AUTOSAR XML (schema 4-2-2)
package /Acme/Types
  base type Octet: category=FIXED_LENGTH, base-type-size=8, base-type-encoding=NONE, native-declaration=uint8
  impl type RecordId: category=VALUE, base-type=Octet
package /Acme/Interfaces
  client server interface IRecords
    operation ReadRecord
      arg id: type=RecordId, direction=IN
    operation ReadOther
      arg id: type=RecordId, direction=IN
    operation Reset
  client server interface IOther
    operation Ping
  sender receiver interface ISignals
    data Value: type=RecordId
package /Acme/Components
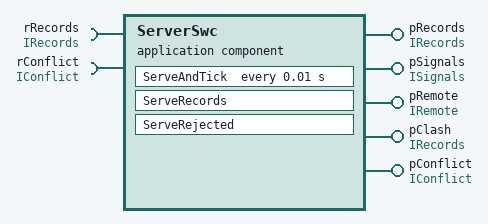
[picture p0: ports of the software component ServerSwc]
  application sw component type ServerSwc
    provide port pRecords: provided-interface=IRecords
      provided-com-specs:
        operation=ReadRecord, queue-length=1
        operation=ReadOther, queue-length=2
        operation=Reset, queue-length=1
    provide port pSignals: provided-interface=ISignals
    require port rRecords: required-interface=IRecords
    provide port pRemote: provided-interface=IRemote
    provide port pClash: provided-interface=IRecords
    provide port pConflict: provided-interface=IConflict
    require port rConflict: required-interface=IConflict
    provide/require port prRecords: provided-required-interface=IRecords
    behavior Behavior
      operation invoked event E_ReadRecord: start-on-event=ServeRecords, operation=pRecords.ReadRecord
      operation invoked event E_ReadOther: start-on-event=ServeRecords, operation=pRecords.ReadOther
      timing event E_Tick: start-on-event=ServeAndTick, period=0.01
      13 x operation invoked event:
        E_Reset: start-on-event=ServeAndTick, operation=pRecords.Reset
        E_Remote: start-on-event=ServeRejected, operation=pRemote.Serve
        E_Clash: start-on-event=ServeRejected, operation=pClash.ReadRecord
        E_Conflict: start-on-event=ServeRejected, operation=pConflict.Serve
        E_Signal: start-on-event=ServeRejected, operation=pSignals.Value
        E_Require: start-on-event=ServeRejected, operation=rRecords.ReadRecord
        E_Missing: start-on-event=ServeRejected, operation=pRecords.Missing
        E_Foreign: start-on-event=ServeRejected, operation=pRecords.ReadRecord
        E_Elsewhere: start-on-event=ServeRejected, operation=pRecords.Ping
        E_NoIref: start-on-event=ServeRejected
        E_NoTarget: start-on-event=ServeRejected, operation=pRecords
        E_PrPort: start-on-event=ServeRejected, operation=prRecords.ReadRecord
        E_Bare: start-on-event=ServeRejected, operation=pRecords.ReadRecord
      runnable ServeRecords: can-be-invoked-concurrently=true
      runnable ServeAndTick
      runnable ServeRejected
package /Acme/Clients
  application sw component type ClientSwc
    provide port pRecords: provided-interface=IRecords
